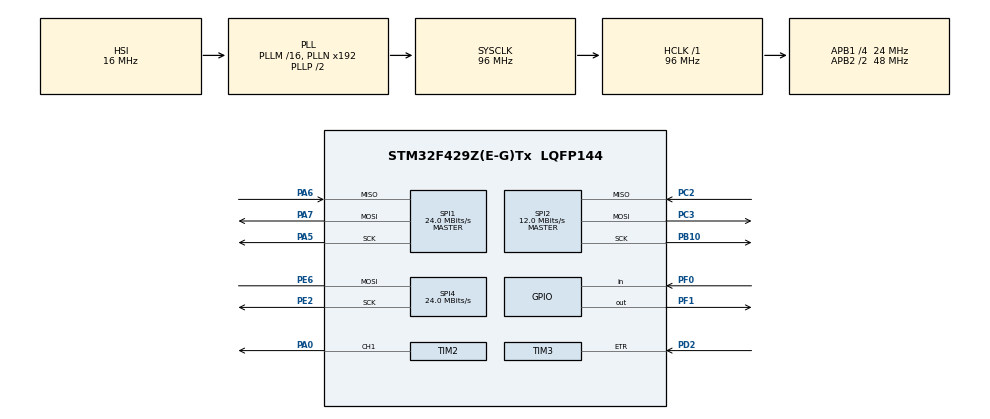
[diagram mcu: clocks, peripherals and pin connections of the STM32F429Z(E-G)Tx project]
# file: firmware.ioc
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Mcu.Family=STM32F4
Mcu.Name=STM32F429Z(E-G)Tx
Mcu.Package=LQFP144
NVIC.PriorityGroup=NVIC_PRIORITYGROUP_4
PA0/WKUP.Signal=S_TIM2_CH1_ETR
PA4.Signal=SPI1_NSS
PA5.Mode=Full_Duplex_Master
PA5.Signal=SPI1_SCK
PA6.Mode=Full_Duplex_Master
PA6.Signal=SPI1_MISO
PA7.Mode=Full_Duplex_Master
PA7.Signal=SPI1_MOSI
PB10.Mode=Full_Duplex_Master
PB10.Signal=SPI2_SCK
PC2.Mode=Full_Duplex_Master
PC2.Signal=SPI2_MISO
PC3.Mode=Full_Duplex_Master
PC3.Signal=SPI2_MOSI
PD2.Signal=S_TIM3_ETR
PE2.Mode=Simplex_Bidirectional_Master
PE2.Signal=SPI4_SCK
PE6.Mode=Simplex_Bidirectional_Master
PE6.Signal=SPI4_MOSI
PF0.Signal=GPIO_Input
PF1.Signal=GPIO_Output
ProjectManager.HeapSize=0x200
ProjectManager.StackSize=0x400
ProjectManager.TargetToolchain=STM32CubeIDE
RCC.48MHZClocksFreq_Value=48000000
RCC.AHBFreq_Value=96000000
RCC.APB1CLKDivider=RCC_HCLK_DIV4
RCC.APB1Freq_Value=24000000
RCC.APB1TimFreq_Value=48000000
RCC.APB2CLKDivider=RCC_HCLK_DIV2
RCC.APB2Freq_Value=48000000
RCC.APB2TimFreq_Value=96000000
RCC.CortexFreq_Value=96000000
RCC.HCLKFreq_Value=96000000
RCC.HSE_VALUE=25000000
RCC.HSI_VALUE=16000000
RCC.LSE_VALUE=32768
RCC.SYSCLKFreq_VALUE=96000000
RCC.SYSCLKSource=RCC_SYSCLKSOURCE_PLLCLK
RCC.VCOOutputFreq_Value=192000000
SH.S_TIM2_CH1_ETR.0=TIM2_CH1,PWM Generation1 CH1
SH.S_TIM3_ETR.0=TIM3_ETR,TriggerSource_ETR
SPI1.BaudRatePrescaler=SPI_BAUDRATEPRESCALER_2
SPI1.CalculateBaudRate=24.0 MBits/s
SPI1.DataSize=SPI_DATASIZE_16BIT
SPI1.Direction=SPI_DIRECTION_2LINES
SPI1.Mode=SPI_MODE_MASTER
SPI1.VirtualType=VM_MASTER
SPI2.CalculateBaudRate=12.0 MBits/s
SPI2.Direction=SPI_DIRECTION_2LINES
SPI2.Mode=SPI_MODE_MASTER
SPI2.VirtualType=VM_MASTER
SPI4.CalculateBaudRate=24.0 MBits/s
SPI4.Direction=SPI_DIRECTION_1LINE
SPI4.Mode=SPI_MODE_MASTER
SPI4.VirtualType=VM_MASTER
TIM2.AutoReloadPreload=TIM_AUTORELOAD_PRELOAD_ENABLE
TIM2.Channel-PWM\ Generation1\ CH1=TIM_CHANNEL_1
VP_TIM2_VS_ClockSourceINT.Mode=Internal
VP_TIM3_VS_ControllerModeClock.Mode=Clock Mode
board=custom

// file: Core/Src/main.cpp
/* USER CODE BEGIN Header */
/**
  ******************************************************************************
  * @file           : main.c
  * @brief          : Main program body
  ******************************************************************************
  * @attention
  *
  * Copyright (c) 2024 STMicroelectronics.
  * All rights reserved.
  *
  * This software is licensed under terms that can be found in the LICENSE file
  * in the root directory of this software component.
  * If no LICENSE file comes with this software, it is provided AS-IS.
  *
  ******************************************************************************
  */
/* USER CODE END Header */
#include "main.h"

/* USER CODE BEGIN Includes */
#include "spin_coater/spin_coater.h"
/* USER CODE END Includes */

SPI_HandleTypeDef hspi1;
SPI_HandleTypeDef hspi2;
SPI_HandleTypeDef hspi4;

TIM_HandleTypeDef htim2;
TIM_HandleTypeDef htim3;

void SystemClock_Config(void);
static void MX_GPIO_Init(void);
static void MX_SPI1_Init(void);
static void MX_TIM2_Init(void);
static void MX_TIM3_Init(void);
static void MX_SPI4_Init(void);
static void MX_SPI2_Init(void);

int main(void)
{

  /* MCU Configuration--------------------------------------------------------*/

  /* Reset of all peripherals, Initializes the Flash interface and the Systick. */
  HAL_Init();

  /* Configure the system clock */
  SystemClock_Config();

  /* Initialize all configured peripherals */
  MX_GPIO_Init();
  MX_SPI1_Init();
  MX_TIM2_Init();
  MX_TIM3_Init();
  MX_SPI4_Init();
  MX_SPI2_Init();
  /* USER CODE BEGIN 2 */
  SpinCoater spinCoater = SpinCoater::withDefaultConfiguration(&hspi1, &hspi4, &hspi2, &htim2, &htim3);
  /* USER CODE END 2 */

  /* Infinite loop */
  while (1)
  {
	  spinCoater.tick();
  }
}

void SystemClock_Config(void)
{
  RCC_OscInitTypeDef RCC_OscInitStruct = {0};
  RCC_ClkInitTypeDef RCC_ClkInitStruct = {0};

  /** Configure the main internal regulator output voltage
  */
  __HAL_RCC_PWR_CLK_ENABLE();
  __HAL_PWR_VOLTAGESCALING_CONFIG(PWR_REGULATOR_VOLTAGE_SCALE3);

  /** Initializes the RCC Oscillators according to the specified parameters
  * in the RCC_OscInitTypeDef structure.
  */
  RCC_OscInitStruct.OscillatorType = RCC_OSCILLATORTYPE_HSI;
  RCC_OscInitStruct.HSIState = RCC_HSI_ON;
  RCC_OscInitStruct.HSICalibrationValue = RCC_HSICALIBRATION_DEFAULT;
  RCC_OscInitStruct.PLL.PLLState = RCC_PLL_ON;
  RCC_OscInitStruct.PLL.PLLSource = RCC_PLLSOURCE_HSI;
  RCC_OscInitStruct.PLL.PLLM = 16;
  RCC_OscInitStruct.PLL.PLLN = 192;
  RCC_OscInitStruct.PLL.PLLP = RCC_PLLP_DIV2;
  RCC_OscInitStruct.PLL.PLLQ = 4;
  if (HAL_RCC_OscConfig(&RCC_OscInitStruct) != HAL_OK)
  {
    Error_Handler();
  }

  /** Initializes the CPU, AHB and APB buses clocks
  */
  RCC_ClkInitStruct.ClockType = RCC_CLOCKTYPE_HCLK|RCC_CLOCKTYPE_SYSCLK
                              |RCC_CLOCKTYPE_PCLK1|RCC_CLOCKTYPE_PCLK2;
  RCC_ClkInitStruct.SYSCLKSource = RCC_SYSCLKSOURCE_PLLCLK;
  RCC_ClkInitStruct.AHBCLKDivider = RCC_SYSCLK_DIV1;
  RCC_ClkInitStruct.APB1CLKDivider = RCC_HCLK_DIV4;
  RCC_ClkInitStruct.APB2CLKDivider = RCC_HCLK_DIV2;

  if (HAL_RCC_ClockConfig(&RCC_ClkInitStruct, FLASH_LATENCY_3) != HAL_OK)
  {
    Error_Handler();
  }
}

static void MX_SPI1_Init(void)
{

  /* SPI1 parameter configuration*/
  hspi1.Instance = SPI1;
  hspi1.Init.Mode = SPI_MODE_MASTER;
  hspi1.Init.Direction = SPI_DIRECTION_2LINES;
  hspi1.Init.DataSize = SPI_DATASIZE_16BIT;
  hspi1.Init.CLKPolarity = SPI_POLARITY_LOW;
  hspi1.Init.CLKPhase = SPI_PHASE_1EDGE;
  hspi1.Init.NSS = SPI_NSS_SOFT;
  hspi1.Init.BaudRatePrescaler = SPI_BAUDRATEPRESCALER_2;
  hspi1.Init.FirstBit = SPI_FIRSTBIT_MSB;
  hspi1.Init.TIMode = SPI_TIMODE_DISABLE;
  hspi1.Init.CRCCalculation = SPI_CRCCALCULATION_DISABLE;
  hspi1.Init.CRCPolynomial = 10;
  if (HAL_SPI_Init(&hspi1) != HAL_OK)
  {
    Error_Handler();
  }

}

static void MX_SPI2_Init(void)
{

  /* SPI2 parameter configuration*/
  hspi2.Instance = SPI2;
  hspi2.Init.Mode = SPI_MODE_MASTER;
  hspi2.Init.Direction = SPI_DIRECTION_2LINES;
  hspi2.Init.DataSize = SPI_DATASIZE_8BIT;
  hspi2.Init.CLKPolarity = SPI_POLARITY_LOW;
  hspi2.Init.CLKPhase = SPI_PHASE_1EDGE;
  hspi2.Init.NSS = SPI_NSS_SOFT;
  hspi2.Init.BaudRatePrescaler = SPI_BAUDRATEPRESCALER_2;
  hspi2.Init.FirstBit = SPI_FIRSTBIT_MSB;
  hspi2.Init.TIMode = SPI_TIMODE_DISABLE;
  hspi2.Init.CRCCalculation = SPI_CRCCALCULATION_DISABLE;
  hspi2.Init.CRCPolynomial = 10;
  if (HAL_SPI_Init(&hspi2) != HAL_OK)
  {
    Error_Handler();
  }

}

static void MX_SPI4_Init(void)
{

  /* SPI4 parameter configuration*/
  hspi4.Instance = SPI4;
  hspi4.Init.Mode = SPI_MODE_MASTER;
  hspi4.Init.Direction = SPI_DIRECTION_1LINE;
  hspi4.Init.DataSize = SPI_DATASIZE_8BIT;
  hspi4.Init.CLKPolarity = SPI_POLARITY_LOW;
  hspi4.Init.CLKPhase = SPI_PHASE_1EDGE;
  hspi4.Init.NSS = SPI_NSS_SOFT;
  hspi4.Init.BaudRatePrescaler = SPI_BAUDRATEPRESCALER_2;
  hspi4.Init.FirstBit = SPI_FIRSTBIT_MSB;
  hspi4.Init.TIMode = SPI_TIMODE_DISABLE;
  hspi4.Init.CRCCalculation = SPI_CRCCALCULATION_DISABLE;
  hspi4.Init.CRCPolynomial = 10;
  if (HAL_SPI_Init(&hspi4) != HAL_OK)
  {
    Error_Handler();
  }

}

static void MX_TIM2_Init(void)
{

  TIM_ClockConfigTypeDef sClockSourceConfig = {0};
  TIM_MasterConfigTypeDef sMasterConfig = {0};
  TIM_OC_InitTypeDef sConfigOC = {0};

  htim2.Instance = TIM2;
  htim2.Init.Prescaler = 0;
  htim2.Init.CounterMode = TIM_COUNTERMODE_UP;
  htim2.Init.Period = 4294967295;
  htim2.Init.ClockDivision = TIM_CLOCKDIVISION_DIV1;
  htim2.Init.AutoReloadPreload = TIM_AUTORELOAD_PRELOAD_ENABLE;
  if (HAL_TIM_Base_Init(&htim2) != HAL_OK)
  {
    Error_Handler();
  }
  sClockSourceConfig.ClockSource = TIM_CLOCKSOURCE_INTERNAL;
  if (HAL_TIM_ConfigClockSource(&htim2, &sClockSourceConfig) != HAL_OK)
  {
    Error_Handler();
  }
  if (HAL_TIM_PWM_Init(&htim2) != HAL_OK)
  {
    Error_Handler();
  }
  sMasterConfig.MasterOutputTrigger = TIM_TRGO_RESET;
  sMasterConfig.MasterSlaveMode = TIM_MASTERSLAVEMODE_DISABLE;
  if (HAL_TIMEx_MasterConfigSynchronization(&htim2, &sMasterConfig) != HAL_OK)
  {
    Error_Handler();
  }
  sConfigOC.OCMode = TIM_OCMODE_PWM1;
  sConfigOC.Pulse = 0;
  sConfigOC.OCPolarity = TIM_OCPOLARITY_HIGH;
  sConfigOC.OCFastMode = TIM_OCFAST_DISABLE;
  if (HAL_TIM_PWM_ConfigChannel(&htim2, &sConfigOC, TIM_CHANNEL_1) != HAL_OK)
  {
    Error_Handler();
  }
  HAL_TIM_MspPostInit(&htim2);

}

static void MX_TIM3_Init(void)
{

  TIM_SlaveConfigTypeDef sSlaveConfig = {0};
  TIM_MasterConfigTypeDef sMasterConfig = {0};

  htim3.Instance = TIM3;
  htim3.Init.Prescaler = 0;
  htim3.Init.CounterMode = TIM_COUNTERMODE_UP;
  htim3.Init.Period = 65535;
  htim3.Init.ClockDivision = TIM_CLOCKDIVISION_DIV1;
  htim3.Init.AutoReloadPreload = TIM_AUTORELOAD_PRELOAD_DISABLE;
  if (HAL_TIM_Base_Init(&htim3) != HAL_OK)
  {
    Error_Handler();
  }
  sSlaveConfig.SlaveMode = TIM_SLAVEMODE_EXTERNAL1;
  sSlaveConfig.InputTrigger = TIM_TS_ETRF;
  sSlaveConfig.TriggerPolarity = TIM_TRIGGERPOLARITY_NONINVERTED;
  sSlaveConfig.TriggerPrescaler = TIM_TRIGGERPRESCALER_DIV1;
  sSlaveConfig.TriggerFilter = 0;
  if (HAL_TIM_SlaveConfigSynchro(&htim3, &sSlaveConfig) != HAL_OK)
  {
    Error_Handler();
  }
  sMasterConfig.MasterOutputTrigger = TIM_TRGO_RESET;
  sMasterConfig.MasterSlaveMode = TIM_MASTERSLAVEMODE_DISABLE;
  if (HAL_TIMEx_MasterConfigSynchronization(&htim3, &sMasterConfig) != HAL_OK)
  {
    Error_Handler();
  }

}

static void MX_GPIO_Init(void)
{
  GPIO_InitTypeDef GPIO_InitStruct = {0};

  /* GPIO Ports Clock Enable */
  __HAL_RCC_GPIOE_CLK_ENABLE();
  __HAL_RCC_GPIOF_CLK_ENABLE();
  __HAL_RCC_GPIOC_CLK_ENABLE();
  __HAL_RCC_GPIOA_CLK_ENABLE();
  __HAL_RCC_GPIOB_CLK_ENABLE();
  __HAL_RCC_GPIOD_CLK_ENABLE();

  /*Configure GPIO pin Output Level */
  HAL_GPIO_WritePin(GPIOF, GPIO_PIN_1, GPIO_PIN_RESET);

  /*Configure GPIO pin : PF0 */
  GPIO_InitStruct.Pin = GPIO_PIN_0;
  GPIO_InitStruct.Mode = GPIO_MODE_INPUT;
  GPIO_InitStruct.Pull = GPIO_NOPULL;
  HAL_GPIO_Init(GPIOF, &GPIO_InitStruct);

  /*Configure GPIO pin : PF1 */
  GPIO_InitStruct.Pin = GPIO_PIN_1;
  GPIO_InitStruct.Mode = GPIO_MODE_OUTPUT_PP;
  GPIO_InitStruct.Pull = GPIO_NOPULL;
  GPIO_InitStruct.Speed = GPIO_SPEED_FREQ_LOW;
  HAL_GPIO_Init(GPIOF, &GPIO_InitStruct);

}

void Error_Handler(void)
{
  __disable_irq();
  while (1)
  {
  }
}
